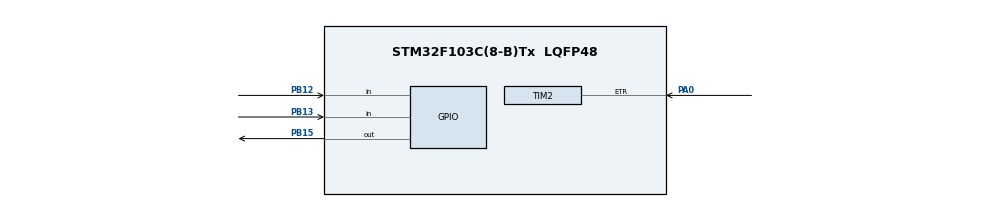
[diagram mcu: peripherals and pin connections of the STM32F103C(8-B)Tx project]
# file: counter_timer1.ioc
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Mcu.Family=STM32F1
Mcu.Name=STM32F103C(8-B)Tx
Mcu.Package=LQFP48
NVIC.PriorityGroup=NVIC_PRIORITYGROUP_4
PA0-WKUP.Signal=S_TIM2_CH1_ETR
PA13.Mode=Serial_Wire
PA13.Signal=SYS_JTMS-SWDIO
PA14.Mode=Serial_Wire
PA14.Signal=SYS_JTCK-SWCLK
PB12.GPIO_PuPd=GPIO_PULLUP
PB12.Signal=GPIO_Input
PB13.GPIO_PuPd=GPIO_PULLUP
PB13.Signal=GPIO_Input
PB15.GPIO_PuPd=GPIO_PULLUP
PB15.Signal=GPIO_Output
PD0-OSC_IN.Mode=HSE-External-Oscillator
PD0-OSC_IN.Signal=RCC_OSC_IN
PD1-OSC_OUT.Mode=HSE-External-Oscillator
PD1-OSC_OUT.Signal=RCC_OSC_OUT
ProjectManager.HeapSize=0x200
ProjectManager.StackSize=0x400
ProjectManager.TargetToolchain=MDK-ARM V5.27
RCC.APB1Freq_Value=8000000
RCC.APB2Freq_Value=8000000
RCC.SYSCLKSource=RCC_SYSCLKSOURCE_HSE
SH.S_TIM2_CH1_ETR.0=TIM2_ETR,ClockSourceETR_Mode2
board=custom

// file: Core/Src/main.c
/* USER CODE BEGIN Header */
/**
  ******************************************************************************
  * @file           : main.c
  * @brief          : Main program body
  ******************************************************************************
  * @attention
  *
  * <h2><center>&copy; Copyright (c) 2020 STMicroelectronics.
  * All rights reserved.</center></h2>
  *
  * This software component is licensed by ST under BSD 3-Clause license,
  * the "License"; You may not use this file except in compliance with the
  * License. You may obtain a copy of the License at:
  *                        opensource.org/licenses/BSD-3-Clause
  *
  ******************************************************************************
  */
/* USER CODE END Header */
#include "main.h"

TIM_HandleTypeDef htim2;

void SystemClock_Config(void);
static void MX_GPIO_Init(void);
static void MX_TIM2_Init(void);
/* USER CODE BEGIN PFP */
volatile short k = 0;
/* USER CODE END PFP */

int main(void)
{

  /* MCU Configuration--------------------------------------------------------*/

  /* Reset of all peripherals, Initializes the Flash interface and the Systick. */
  HAL_Init();

  /* Configure the system clock */
  SystemClock_Config();

  /* Initialize all configured peripherals */
  MX_GPIO_Init();
  MX_TIM2_Init();
  /* USER CODE BEGIN 2 */
	HAL_TIM_Base_Start(&htim2);
  /* USER CODE END 2 */
  /* Infinite loop */
  /* USER CODE BEGIN WHILE */
  while (1){
    while (HAL_GPIO_ReadPin(GPIOB,GPIO_PIN_12) == 1){
			HAL_GPIO_WritePin(GPIOB,GPIO_PIN_15,1);
			HAL_Delay(k);
			HAL_GPIO_WritePin(GPIOB,GPIO_PIN_15,0);
			HAL_Delay(20-k);
    }
		k++;
		if (k == 21){
			k = 0;
		}
		while (HAL_GPIO_ReadPin(GPIOB,GPIO_PIN_12) == 0){
			HAL_GPIO_WritePin(GPIOB,GPIO_PIN_15,1);
			HAL_Delay(k);
			HAL_GPIO_WritePin(GPIOB,GPIO_PIN_15,0);
			HAL_Delay(20-k);
		}
  }

}

void SystemClock_Config(void)
{
  RCC_OscInitTypeDef RCC_OscInitStruct = {0};
  RCC_ClkInitTypeDef RCC_ClkInitStruct = {0};

  /** Initializes the RCC Oscillators according to the specified parameters
  * in the RCC_OscInitTypeDef structure.
  */
  RCC_OscInitStruct.OscillatorType = RCC_OSCILLATORTYPE_HSE;
  RCC_OscInitStruct.HSEState = RCC_HSE_ON;
  RCC_OscInitStruct.PLL.PLLState = RCC_PLL_NONE;
  if (HAL_RCC_OscConfig(&RCC_OscInitStruct) != HAL_OK)
  {
    Error_Handler();
  }
  /** Initializes the CPU, AHB and APB buses clocks
  */
  RCC_ClkInitStruct.ClockType = RCC_CLOCKTYPE_HCLK|RCC_CLOCKTYPE_SYSCLK
                              |RCC_CLOCKTYPE_PCLK1|RCC_CLOCKTYPE_PCLK2;
  RCC_ClkInitStruct.SYSCLKSource = RCC_SYSCLKSOURCE_HSE;
  RCC_ClkInitStruct.AHBCLKDivider = RCC_SYSCLK_DIV1;
  RCC_ClkInitStruct.APB1CLKDivider = RCC_HCLK_DIV1;
  RCC_ClkInitStruct.APB2CLKDivider = RCC_HCLK_DIV1;

  if (HAL_RCC_ClockConfig(&RCC_ClkInitStruct, FLASH_LATENCY_0) != HAL_OK)
  {
    Error_Handler();
  }
}

static void MX_TIM2_Init(void)
{

  TIM_ClockConfigTypeDef sClockSourceConfig = {0};
  TIM_MasterConfigTypeDef sMasterConfig = {0};

  htim2.Instance = TIM2;
  htim2.Init.Prescaler = 0;
  htim2.Init.CounterMode = TIM_COUNTERMODE_UP;
  htim2.Init.Period = 65535;
  htim2.Init.ClockDivision = TIM_CLOCKDIVISION_DIV1;
  htim2.Init.AutoReloadPreload = TIM_AUTORELOAD_PRELOAD_DISABLE;
  if (HAL_TIM_Base_Init(&htim2) != HAL_OK)
  {
    Error_Handler();
  }
  sClockSourceConfig.ClockSource = TIM_CLOCKSOURCE_ETRMODE2;
  sClockSourceConfig.ClockPolarity = TIM_CLOCKPOLARITY_NONINVERTED;
  sClockSourceConfig.ClockPrescaler = TIM_CLOCKPRESCALER_DIV1;
  sClockSourceConfig.ClockFilter = 0;
  if (HAL_TIM_ConfigClockSource(&htim2, &sClockSourceConfig) != HAL_OK)
  {
    Error_Handler();
  }
  sMasterConfig.MasterOutputTrigger = TIM_TRGO_RESET;
  sMasterConfig.MasterSlaveMode = TIM_MASTERSLAVEMODE_DISABLE;
  if (HAL_TIMEx_MasterConfigSynchronization(&htim2, &sMasterConfig) != HAL_OK)
  {
    Error_Handler();
  }

}

static void MX_GPIO_Init(void)
{
  GPIO_InitTypeDef GPIO_InitStruct = {0};

  /* GPIO Ports Clock Enable */
  __HAL_RCC_GPIOD_CLK_ENABLE();
  __HAL_RCC_GPIOA_CLK_ENABLE();
  __HAL_RCC_GPIOB_CLK_ENABLE();

  /*Configure GPIO pin Output Level */
  HAL_GPIO_WritePin(GPIOB, GPIO_PIN_15, GPIO_PIN_RESET);

  /*Configure GPIO pins : PB12 PB13 */
  GPIO_InitStruct.Pin = GPIO_PIN_12|GPIO_PIN_13;
  GPIO_InitStruct.Mode = GPIO_MODE_INPUT;
  GPIO_InitStruct.Pull = GPIO_PULLUP;
  HAL_GPIO_Init(GPIOB, &GPIO_InitStruct);

  /*Configure GPIO pin : PB15 */
  GPIO_InitStruct.Pin = GPIO_PIN_15;
  GPIO_InitStruct.Mode = GPIO_MODE_OUTPUT_PP;
  GPIO_InitStruct.Pull = GPIO_PULLUP;
  GPIO_InitStruct.Speed = GPIO_SPEED_FREQ_LOW;
  HAL_GPIO_Init(GPIOB, &GPIO_InitStruct);

}

void Error_Handler(void)
{
}

/************************ (C) COPYRIGHT STMicroelectronics *****END OF FILE****/
